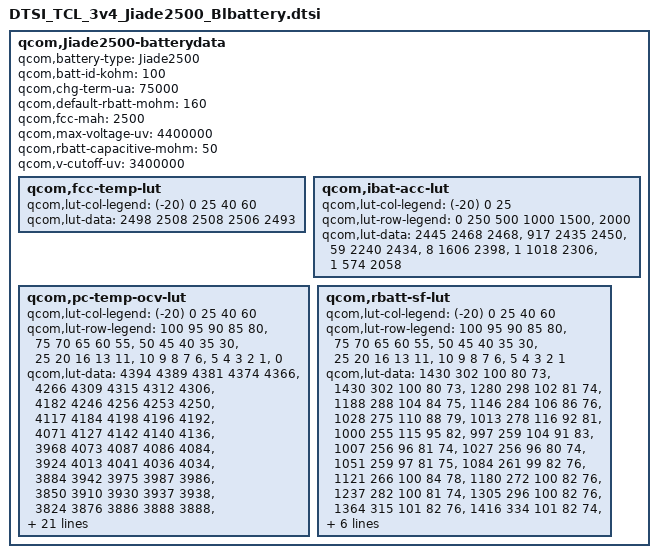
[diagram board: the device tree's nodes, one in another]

qcom,Jiade2500-batterydata {
	qcom,battery-type = "Jiade2500";
	qcom,batt-id-kohm = <100>;
	qcom,chg-term-ua = <75000>;
	qcom,default-rbatt-mohm = <160>;
	qcom,fcc-mah = <2500>;
	qcom,max-voltage-uv = <4400000>;
	qcom,rbatt-capacitive-mohm = <50>;
	qcom,v-cutoff-uv = <3400000>;

	qcom,fcc-temp-lut {
		qcom,lut-col-legend = <(-20) 0 25 40 60>;
		qcom,lut-data = <2498 2508 2508 2506 2493>;
	};

	qcom,ibat-acc-lut {
		qcom,lut-col-legend = <(-20) 0 25>;
		qcom,lut-row-legend = <0 250 500 1000 1500>,
					<2000>;
		qcom,lut-data = <2445 2468 2468>,
				<917 2435 2450>,
				<59 2240 2434>,
				<8 1606 2398>,
				<1 1018 2306>,
				<1 574 2058>;
	};

	qcom,pc-temp-ocv-lut {
		qcom,lut-col-legend = <(-20) 0 25 40 60>;
		qcom,lut-row-legend = <100 95 90 85 80>,
					<75 70 65 60 55>,
					<50 45 40 35 30>,
					<25 20 16 13 11>,
					<10 9 8 7 6>,
					<5 4 3 2 1>,
					<0>;
		qcom,lut-data = <4394 4389 4381 4374 4366>,
				<4266 4309 4315 4312 4306>,
				<4182 4246 4256 4253 4250>,
				<4117 4184 4198 4196 4192>,
				<4071 4127 4142 4140 4136>,
				<3968 4073 4087 4086 4084>,
				<3924 4013 4041 4036 4034>,
				<3884 3942 3975 3987 3986>,
				<3850 3910 3930 3937 3938>,
				<3824 3876 3886 3888 3888>,
				<3806 3844 3854 3854 3855>,
				<3790 3817 3827 3828 3828>,
				<3774 3794 3805 3806 3806>,
				<3758 3776 3786 3786 3786>,
				<3742 3762 3768 3766 3763>,
				<3720 3746 3752 3746 3736>,
				<3695 3730 3734 3726 3714>,
				<3671 3716 3714 3706 3693>,
				<3649 3704 3696 3688 3676>,
				<3632 3696 3689 3681 3670>,
				<3624 3691 3686 3680 3668>,
				<3614 3685 3686 3678 3666>,
				<3600 3678 3683 3676 3664>,
				<3584 3668 3678 3671 3658>,
				<3564 3653 3669 3660 3644>,
				<3539 3629 3644 3631 3612>,
				<3506 3592 3600 3584 3564>,
				<3461 3538 3540 3523 3502>,
				<3392 3456 3456 3438 3416>,
				<3276 3315 3319 3299 3280>,
				<3000 3000 3000 3000 3000>;
	};

	qcom,rbatt-sf-lut {
		qcom,lut-col-legend = <(-20) 0 25 40 60>;
		qcom,lut-row-legend = <100 95 90 85 80>,
					<75 70 65 60 55>,
					<50 45 40 35 30>,
					<25 20 16 13 11>,
					<10 9 8 7 6>,
					<5 4 3 2 1>;
		qcom,lut-data = <1430 302 100 80 73>,
				<1430 302 100 80 73>,
				<1280 298 102 81 74>,
				<1188 288 104 84 75>,
				<1146 284 106 86 76>,
				<1028 275 110 88 79>,
				<1013 278 116 92 81>,
				<1000 255 115 95 82>,
				<997 259 104 91 83>,
				<1007 256 96 81 74>,
				<1027 256 96 80 74>,
				<1051 259 97 81 75>,
				<1084 261 99 82 76>,
				<1121 266 100 84 78>,
				<1180 272 100 82 76>,
				<1237 282 100 81 74>,
				<1305 296 100 82 76>,
				<1364 315 101 82 76>,
				<1416 334 101 82 74>,
				<1423 346 101 82 76>,
				<1424 351 102 84 78>,
				<1435 358 105 86 79>,
				<1476 371 109 89 80>,
				<1582 386 111 91 82>,
				<1731 400 114 91 81>,
				<1905 416 111 88 78>,
				<2155 436 109 87 79>,
				<2504 462 112 89 80>,
				<3156 504 118 92 82>,
				<6311 1007 235 184 165>;
	};
};
/* TEST_DB_ID=TEST_ID_NOT_SET */
